AUTOSAR XML (schema 4-3-0)
package /CompositionARPkgName
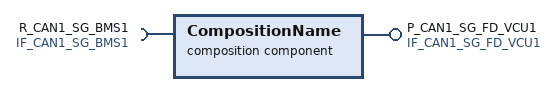
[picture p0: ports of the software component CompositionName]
  composition sw component type CompositionName
    require port R_CAN1_SG_BMS1: nonqueued-receiver-com-spec{data-element=CAN1_SG_BMS1, handle-out-of-range=DEFAULT, enable-update=true, init-value=constant-reference=Init_CAN1_SG_BMS1}, required-interface=IF_CAN1_SG_BMS1
    provide port P_CAN1_SG_FD_VCU1: nonqueued-sender-com-spec{data-element=CAN1_SG_FD_VCU1, handle-out-of-range=DEFAULT, init-value=constant-reference=Init_CAN1_SG_FD_VCU1}, provided-interface=IF_CAN1_SG_FD_VCU1
    9 x component:
      BswMTest: type=BswMTest_type
      SWC_CDD: type=SWC_CDD_type
      SWC_DID: type=SWC_DID_type
      SWC_FDC: type=SWC_FDC_type
      SWC_IMU: type=SWC_IMU_type
      SWC_NVM: type=SWC_NVM_type
      SWC_UART: type=SWC_UART_type
      SWC_VES: type=SWC_VES_type
      SWC_UDS: type=SWC_UDS_type
    delegate SWC_FDC.R_CAN1_FCM3 <-> outer port HALR_CAN1_FCM3
    delegate SWC_FDC.P_CAN3_FD_VCU1 <-> outer port HALP_CAN3_FD_VCU1
    connect SWC_CDD.P_HALINCDD -> SWC_FDC.R_HALINCDD
    connect SWC_CDD.P_HALINCDD -> SWC_VES.R_HALINCDD
    connect SWC_CDD.P_HALOUTCDD -> SWC_FDC.R_HALOUTCDD
    connect SWC_DID.P_DIDReadCDD -> SWC_FDC.R_DIDReadCDD
    connect SWC_DID.P_DIDWriteCDD -> SWC_FDC.R_DIDWriteCDD
    connect SWC_FDC.P_AppModeReq -> BswMTest.R_AppModeReq
    connect SWC_FDC.P_E2E_CAN3_VCU1 -> SWC_FDC.R_E2E_CAN3_VCU1
    connect SWC_FDC.P_E2E_CAN4_VCU1 -> SWC_FDC.R_E2E_CAN4_VCU1
    connect SWC_FDC.P_FDCDD_Inner -> SWC_FDC.R_FDCCDD_Inner
    connect SWC_FDC.P_NVMReadCDD_Inner -> SWC_FDC.R_NVMReadCDD_Inner
    connect SWC_FDC.P_NVMWriteCDD_Inner -> SWC_FDC.R_NVMWriteCDD_Inner
    connect SWC_FDC.P_NVMWrite -> SWC_NVM.R_WriteNVData
    connect SWC_FDC.P_WDGCDD -> SWC_FDC.R_WDGCDD
    connect SWC_IMU.P_HAINICDD_IMU -> SWC_FDC.R_HALIN_IMU
    connect SWC_NVM.P_ReadNVData -> SWC_FDC.R_NVMRead
    connect SWC_UART.P_UARTCDD -> SWC_UART.R_UARTCDD
    connect SWC_VES.P_VESCDD -> SWC_VES.R_VESCDD
    connect SWC_UDS.P_UDSCDD -> SWC_FDC.R_UDSCDD
